# PIC32MK0128MCA032 register map
Vendor: Microchip
Registers are 32-bit, read-write, reset 0x0 unless marked. A register's access mark holds for its fields unless they carry their own. Addresses are absolute, and some are shared; only a register's first bit layout is shown; [hi:lo] are bit positions; {n}, {i} and the like mark numbered series.

## CMP4
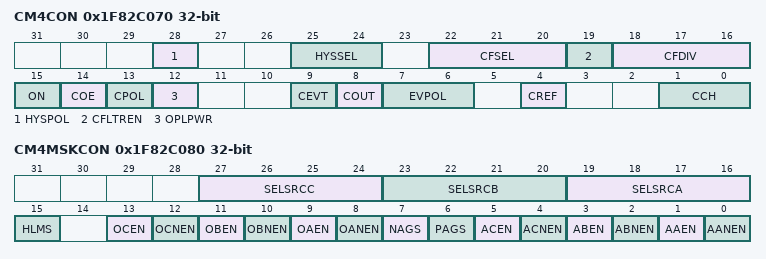
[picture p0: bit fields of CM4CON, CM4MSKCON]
0x1F82C070 CM4CON reset not defined — (power-on value ---x--00-00000000000--0000-0--00)
  [28] HYSPOL — Comparator Hysteresis Polarity Selection
    1=Hysteresis on falling edge, rising edge is accurate; 0=Hysteresis on rising edge, falling edge is accurate
  [25:24] HYSSEL
  [22:20] CFSEL
  [19] CFLTREN
  [18:16] CFDIV
  [15] ON
  [14] COE
  [13] CPOL
  [12] OPLPWR
  [9] CEVT
  [8] COUT ro
  [7:6] EVPOL
  [4] CREF
  [1:0] CCH
0x1F82C080 CM4MSKCON
  [27:24] SELSRCC, [23:20] SELSRCB, [19:16] SELSRCA, [15] HLMS, [13] OCEN, [12] OCNEN, [11] OBEN, [10] OBNEN, [9] OAEN, [8] OANEN, [7] NAGS, [6] PAGS, [5] ACEN, [4] ACNEN, [3] ABEN, [2] ABNEN, [1] AAEN, [0] AANEN

## CMP5
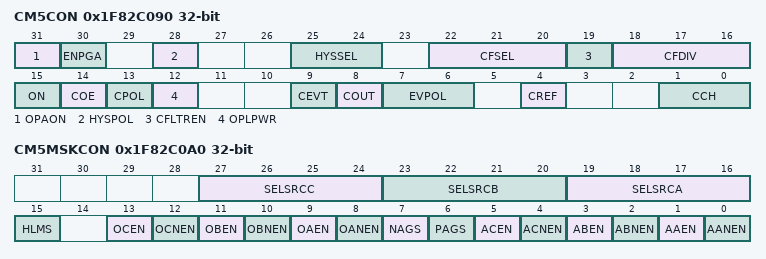
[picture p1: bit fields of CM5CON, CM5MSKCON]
0x1F82C090 CM5CON reset not defined — (power-on value xx-x--00-00000000000--0000-0--00)
  [31] OPAON — Opamp Enable Bit
    1=Opamp Enabled and Connected to Pin; 0=Opamp is disabled and pin is released to other functions
  [30] ENPGA — Opamp Fixed Gain Enable bit
    1=Op amp is operating in Fixed Gain 1X mode; 0=Op amp is operating in Open Loop Mode
  [28] HYSPOL — Comparator Hysteresis Polarity Selection
    1=Hysteresis on falling edge, rising edge is accurate; 0=Hysteresis on rising edge, falling edge is accurate
  [25:24] HYSSEL
  [22:20] CFSEL
  [19] CFLTREN
  [18:16] CFDIV
  [15] ON
  [14] COE
  [13] CPOL
  [12] OPLPWR
  [9] CEVT
  [8] COUT ro
  [7:6] EVPOL
  [4] CREF
  [1:0] CCH
0x1F82C0A0 CM5MSKCON
  [27:24] SELSRCC, [23:20] SELSRCB, [19:16] SELSRCA, [15] HLMS, [13] OCEN, [12] OCNEN, [11] OBEN, [10] OBNEN, [9] OAEN, [8] OANEN, [7] NAGS, [6] PAGS, [5] ACEN, [4] ACNEN, [3] ABEN, [2] ABNEN, [1] AAEN, [0] AANEN

## CDAC1
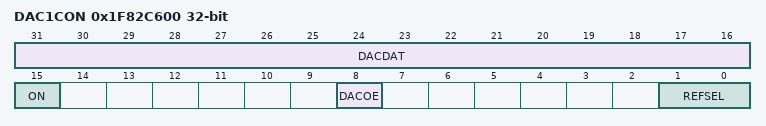
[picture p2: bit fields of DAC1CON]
0x1F82C600 DAC1CON — CDAC Control Register
  [31:16] DACDAT — Data Input Register Bits for the CDAC
  [15] ON — CDAC Enable
    0=The CDAC is Disabled; 1=The CDAC is Enabled
  [8] DACOE — CDAC Output Enable
    0=Output is Disabled; drive to pin is floating; 1=Output is Enabled; CDAC voltage is connected to the pin
  [1:0] REFSEL — Reference Source Select
    0=No Reference Selected (no current consumed); 1=Positive Reference Voltage = External Vref+ Pin; 2=Positive Reference Voltage = 2 * Internal Bandgap Reference Voltage; 3=Positive Reference Voltage = AVdd

## CTMU
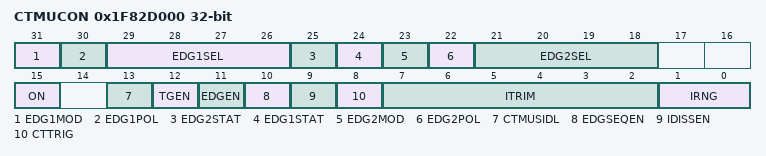
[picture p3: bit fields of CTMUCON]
0x1F82D000 CTMUCON
  [31] EDG1MOD, [30] EDG1POL, [29:26] EDG1SEL, [25] EDG2STAT, [24] EDG1STAT, [23] EDG2MOD, [22] EDG2POL, [21:18] EDG2SEL, [15] ON, [13] CTMUSIDL, [12] TGEN, [11] EDGEN, [10] EDGSEQEN, [9] IDISSEN, [8] CTTRIG, [7:2] ITRIM, [1:0] IRNG

## CLC1
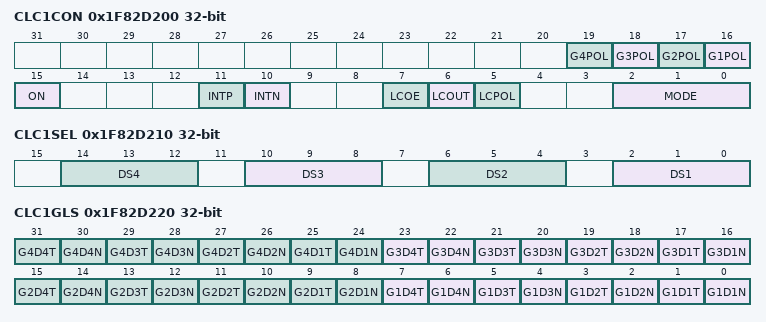
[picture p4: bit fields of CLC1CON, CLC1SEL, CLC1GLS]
0x1F82D200 CLC1CON
  [n+15] G{n}POL (n=1..4), [15] ON, [11] INTP, [10] INTN, [7] LCOE, [6] LCOUT, [5] LCPOL, [2:0] MODE
0x1F82D210 CLC1SEL
  [4n-2:4n-4] DS{n} (n=1..4)
0x1F82D220 CLC1GLS
  [8n-1] G{n}D4T (n=1..4), [8n-2] G{n}D4N (n=1..4), [8n-3] G{n}D3T (n=1..4), [8n-4] G{n}D3N (n=1..4), [8n-5] G{n}D2T (n=1..4), [8n-6] G{n}D2N (n=1..4), [8n-7] G{n}D1T (n=1..4), [8n-8] G{n}D1N (n=1..4)

## gpio_ports_upb
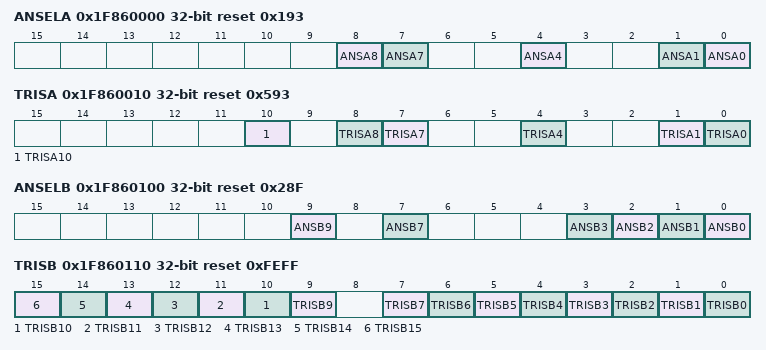
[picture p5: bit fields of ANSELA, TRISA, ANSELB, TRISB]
0x1F860000 ANSELA reset 0x193
  [8] ANSA8, [7] ANSA7, [4] ANSA4, [1] ANSA1, [0] ANSA0
0x1F860010 TRISA reset 0x593
  [10] TRISA10, [8] TRISA8, [7] TRISA7, [4] TRISA4, [1] TRISA1, [0] TRISA0
0x1F860100 ANSELB reset 0x28F
  [9] ANSB9, [7] ANSB7, [n] ANSB{n} (n=0..3)
0x1F860110 TRISB reset 0xFEFF
  [n] TRISB{n} (n=9..15), [n] TRISB{n} (n=0..7)
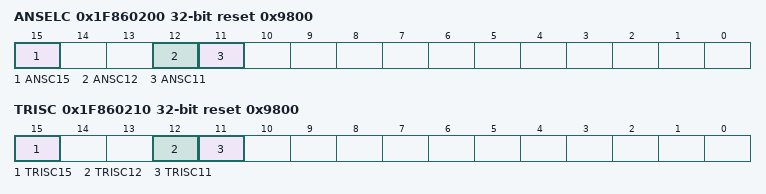
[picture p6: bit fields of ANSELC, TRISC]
0x1F860200 ANSELC reset 0x9800
  [15] ANSC15, [12] ANSC12, [11] ANSC11
0x1F860210 TRISC reset 0x9800
  [15] TRISC15, [12] TRISC12, [11] TRISC11
0x1F860300 ANSELD access not given reset not defined
0x1F860310 TRISD access not given reset not defined

## PORTA
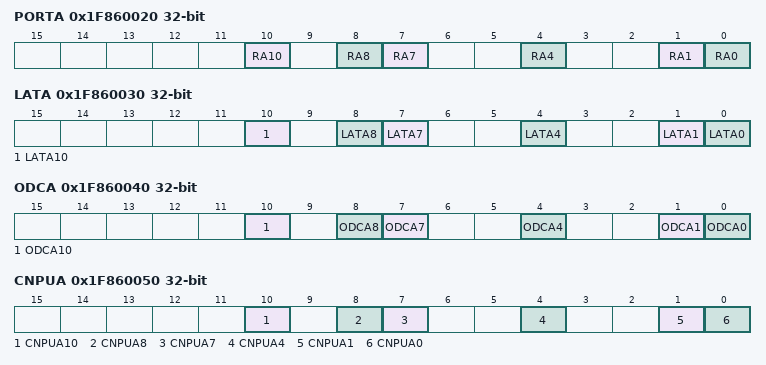
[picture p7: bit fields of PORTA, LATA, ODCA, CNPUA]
0x1F860020 PORTA reset not defined — (power-on value ---------------------x-xx--x--xx)
  [10] RA10, [8] RA8, [7] RA7, [4] RA4, [1] RA1, [0] RA0
0x1F860030 LATA reset not defined — (power-on value ---------------------x-xx--x--xx)
  [10] LATA10, [8] LATA8, [7] LATA7, [4] LATA4, [1] LATA1, [0] LATA0
0x1F860040 ODCA
  [10] ODCA10, [8] ODCA8, [7] ODCA7, [4] ODCA4, [1] ODCA1, [0] ODCA0
0x1F860050 CNPUA
  [10] CNPUA10, [8] CNPUA8, [7] CNPUA7, [4] CNPUA4, [1] CNPUA1, [0] CNPUA0
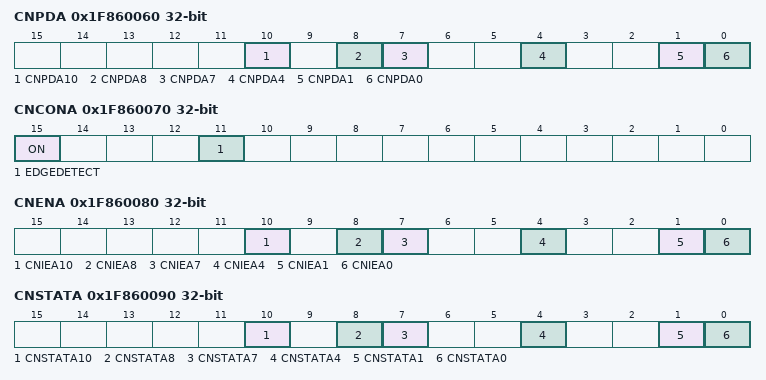
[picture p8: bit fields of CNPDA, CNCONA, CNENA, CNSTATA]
0x1F860060 CNPDA
  [10] CNPDA10, [8] CNPDA8, [7] CNPDA7, [4] CNPDA4, [1] CNPDA1, [0] CNPDA0
0x1F860070 CNCONA
  [15] ON, [11] EDGEDETECT
0x1F860080 CNENA
  [10] CNIEA10, [8] CNIEA8, [7] CNIEA7, [4] CNIEA4, [1] CNIEA1, [0] CNIEA0
0x1F860090 CNSTATA
  [10] CNSTATA10, [8] CNSTATA8, [7] CNSTATA7, [4] CNSTATA4, [1] CNSTATA1, [0] CNSTATA0
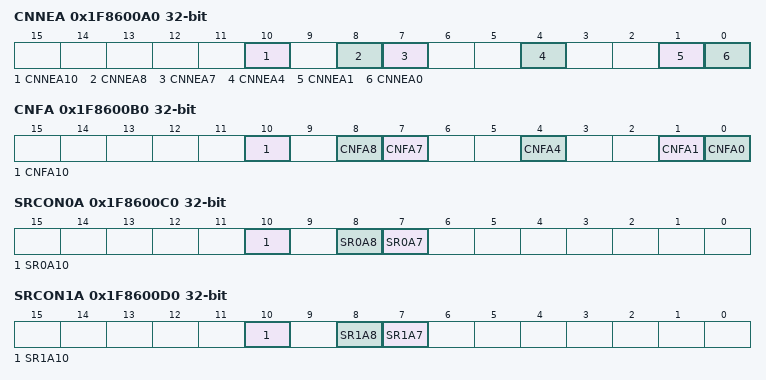
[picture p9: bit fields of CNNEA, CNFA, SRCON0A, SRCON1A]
0x1F8600A0 CNNEA
  [10] CNNEA10, [8] CNNEA8, [7] CNNEA7, [4] CNNEA4, [1] CNNEA1, [0] CNNEA0
0x1F8600B0 CNFA
  [10] CNFA10, [8] CNFA8, [7] CNFA7, [4] CNFA4, [1] CNFA1, [0] CNFA0
0x1F8600C0 SRCON0A
  [10] SR0A10, [8] SR0A8, [7] SR0A7
0x1F8600D0 SRCON1A
  [10] SR1A10, [8] SR1A8, [7] SR1A7
